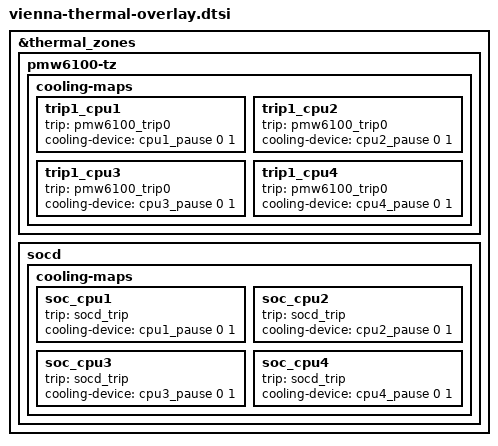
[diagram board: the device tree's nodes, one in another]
// SPDX-License-Identifier: BSD-3-Clause
/*
 * Copyright (c) Qualcomm Technologies, Inc. and/or its subsidiaries.
 */

#include <dt-bindings/thermal/thermal_qti.h>

&thermal_zones {
	pmw6100-tz {
		cooling-maps {
			trip1_cpu1 {
				trip = <&pmw6100_trip0>;
				cooling-device = <&cpu1_pause 0 1>;
			};

			trip1_cpu2 {
				trip = <&pmw6100_trip0>;
				cooling-device = <&cpu2_pause 0 1>;
			};

			trip1_cpu3 {
				trip = <&pmw6100_trip0>;
				cooling-device = <&cpu3_pause 0 1>;
			};

			trip1_cpu4 {
				trip = <&pmw6100_trip0>;
				cooling-device = <&cpu4_pause 0 1>;
			};
		};
	};

	socd {
		cooling-maps {
			soc_cpu1 {
				trip = <&socd_trip>;
				cooling-device = <&cpu1_pause 0 1>;
			};

			soc_cpu2 {
				trip = <&socd_trip>;
				cooling-device = <&cpu2_pause 0 1>;
			};

			soc_cpu3 {
				trip = <&socd_trip>;
				cooling-device = <&cpu3_pause 0 1>;
			};

			soc_cpu4 {
				trip = <&socd_trip>;
				cooling-device = <&cpu4_pause 0 1>;
			};
		};
	};
};

